# STM32F446 register map
File version: 1.9
CPU: CM4 r0p1, little endian, MPU, FPU, 4 interrupt priority bits
Registers are 32-bit, read-write, reset 0x0 unless marked. A register's access mark holds for its fields unless they carry their own. Offsets are from the block's base; [hi:lo] are bit positions; lines under a group give offsets from that group; {n}, {i} and the like mark numbered series.

## TIM6 — Basic timers
Base 0x40001000
Same registers: TIM7 0x40001400
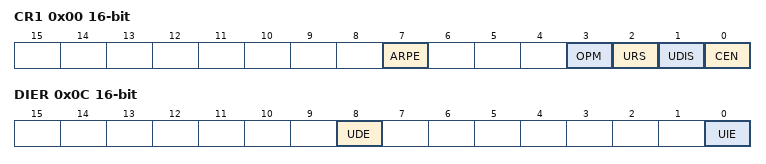
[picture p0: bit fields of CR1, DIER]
0x00 CR1 16-bit — control register 1
  [7] ARPE — Auto-reload preload enable
    0=Disabled (TIMx_APRR register is not buffered); 1=Enabled (TIMx_APRR register is buffered)
  [3] OPM — One-pulse mode
    0=Disabled (Counter is not stopped at update event); 1=Enabled (Counter stops counting at the next update event (clearing the CEN bit))
  [2] URS — Update request source
    0=AnyEvent (Any of counter overflow/underflow, setting UG, or update through slave mode, generates an update interrupt or DMA request); 1=CounterOnly (Only counter overflow/underflow generates an update interrupt or DMA request)
  [1] UDIS — Update disable
    0=Enabled (Update event enabled); 1=Disabled (Update event disabled)
  [0] CEN — Counter enable
    0=Disabled (Counter disabled); 1=Enabled (Counter enabled)
0x04 CR2 16-bit — control register 2
  [6:4] MMS — Master mode selection
    0=Reset (Use UG bit from TIMx_EGR register); 1=Enable (Use CNT bit from TIMx_CEN register); 2=Update (Use the update event)
0x0C DIER 16-bit — DMA/Interrupt enable register
  [8] UDE — Update DMA request enable
    0=Disabled (Update DMA request disabled); 1=Enabled (Update DMA request enabled)
  [0] UIE — Update interrupt enable
    0=Disabled (Update interrupt disabled); 1=Enabled (Update interrupt enabled)
0x10 SR 16-bit — status register
  [0] UIF write-0-clears — Update interrupt flag
    on read: 0=NoUpdateOccurred; 1=UpdatePending (Update interrupt pending) | on write: 0=Clear flag
0x14 EGR 16-bit wo — event generation register
  [0] UG — Update generation
    1=Update (Re-initializes the timer counter and generates an update of the registers.)
0x24 CNT 16-bit — counter
  [15:0] CNT — Low counter value
0x28 PSC 16-bit — prescaler
  [15:0] PSC — Prescaler value
0x2C ARR 16-bit reset 0xFFFF — auto-reload register
  [15:0] ARR — Low Auto-reload value

## CRC — Cryptographic processor
Base 0x40023000
0x00 DR reset 0xFFFFFFFF — Data register
  [31:0] DR — Data Register
0x04 IDR — Independent Data register
  [7:0] IDR
0x08 CR wo — Control register
  [0] RESET — Control regidter
    1=Resets the CRC calculation unit and sets the data register to 0xFFFF FFFF

## OTG_FS_HOST — USB on the go full speed
Base 0x50000400
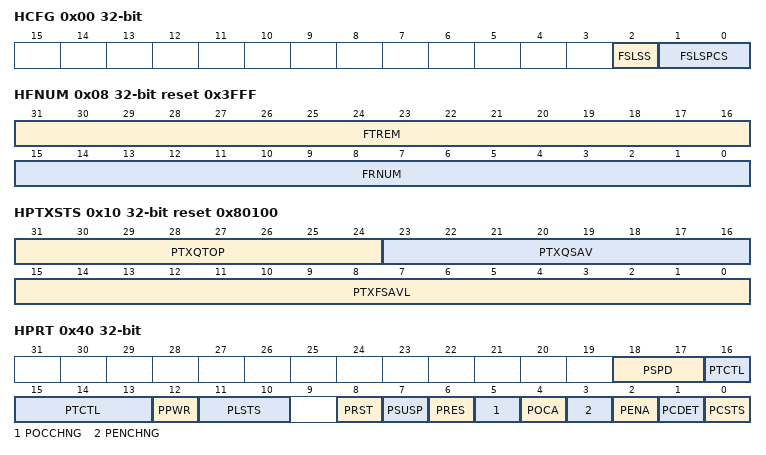
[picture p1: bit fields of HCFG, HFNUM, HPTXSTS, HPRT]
0x00 HCFG — OTG_FS host configuration register (OTG_FS_HCFG)
  [2] FSLSS — FS- and LS-only support
  [1:0] FSLSPCS — FS/LS PHY clock select
0x04 HFIR reset 0xEA60 — OTG_FS Host frame interval register
  [15:0] FRIVL — Frame interval
0x08 HFNUM ro reset 0x3FFF — OTG_FS host frame number/frame time remaining register (OTG_FS_HFNUM)
  [31:16] FTREM — Frame time remaining
  [15:0] FRNUM — Frame number
0x10 HPTXSTS access per field reset 0x80100 — OTG_FS_Host periodic transmit FIFO/queue status register (OTG_FS_HPTXSTS)
  [31:24] PTXQTOP ro — Top of the periodic transmit request queue
  [23:16] PTXQSAV ro — Periodic transmit request queue space available
  [15:0] PTXFSAVL rw — Periodic transmit data FIFO space available
0x14 HAINT ro — OTG_FS Host all channels interrupt register
  [15:0] HAINT — Channel interrupts
0x18 HAINTMSK — OTG_FS host all channels interrupt mask register
  [15:0] HAINTM — Channel interrupt mask
0x40 HPRT access per field — OTG_FS host port control and status register (OTG_FS_HPRT)
  [18:17] PSPD ro — Port speed
  [16:13] PTCTL rw — Port test control
  [12] PPWR rw — Port power
  [11:10] PLSTS ro — Port line status
  [8] PRST rw — Port reset
  [7] PSUSP rw — Port suspend
  [6] PRES rw — Port resume
  [5] POCCHNG rw — Port overcurrent change
  [4] POCA ro — Port overcurrent active
  [3] PENCHNG rw — Port enable/disable change
  [2] PENA rw — Port enable
  [1] PCDET rw — Port connect detected
  [0] PCSTS ro — Port connect status
{0x100+0x20*i} HC{i} (i=0..11) group — Host channel
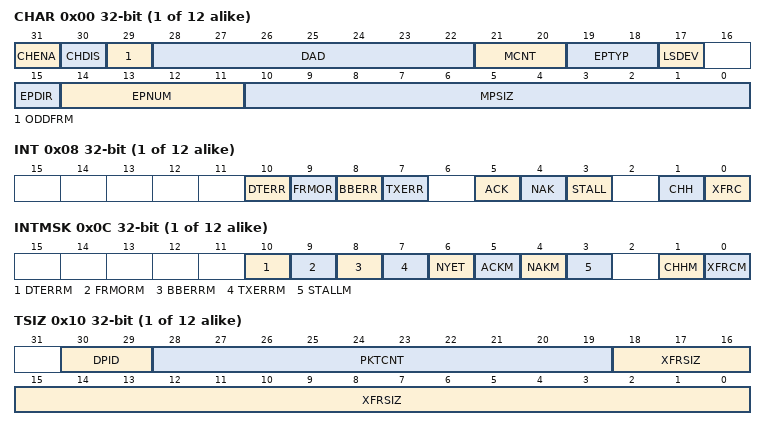
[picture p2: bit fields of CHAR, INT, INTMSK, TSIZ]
  0x00 CHAR — OTG_FS host channel-0 characteristics register (OTG_FS_HCCHAR0)
    [31] CHENA — Channel enable
    [30] CHDIS — Channel disable
    [29] ODDFRM — Odd frame
    [28:22] DAD — Device address
    [21:20] MCNT — Multicount
    [19:18] EPTYP — Endpoint type
    [17] LSDEV — Low-speed device
    [15] EPDIR — Endpoint direction
    [14:11] EPNUM — Endpoint number
    [10:0] MPSIZ — Maximum packet size
  0x08 INT — OTG_FS host channel-0 interrupt register (OTG_FS_HCINT0)
    [10] DTERR — Data toggle error
    [9] FRMOR — Frame overrun
    [8] BBERR — Babble error
    [7] TXERR — Transaction error
    [5] ACK — ACK response received/transmitted interrupt
    [4] NAK — NAK response received interrupt
    [3] STALL — STALL response received interrupt
    [1] CHH — Channel halted
    [0] XFRC — Transfer completed
  0x0C INTMSK — OTG_FS host channel-0 mask register (OTG_FS_HCINTMSK0)
    [10] DTERRM — Data toggle error mask
    [9] FRMORM — Frame overrun mask
    [8] BBERRM — Babble error mask
    [7] TXERRM — Transaction error mask
    [6] NYET — response received interrupt mask
    [5] ACKM — ACK response received/transmitted interrupt mask
    [4] NAKM — NAK response received interrupt mask
    [3] STALLM — STALL response received interrupt mask
    [1] CHHM — Channel halted mask
    [0] XFRCM — Transfer completed mask
  0x10 TSIZ — OTG_FS host channel-0 transfer size register
    [30:29] DPID — Data PID
    [28:19] PKTCNT — Packet count
    [18:0] XFRSIZ — Transfer size
